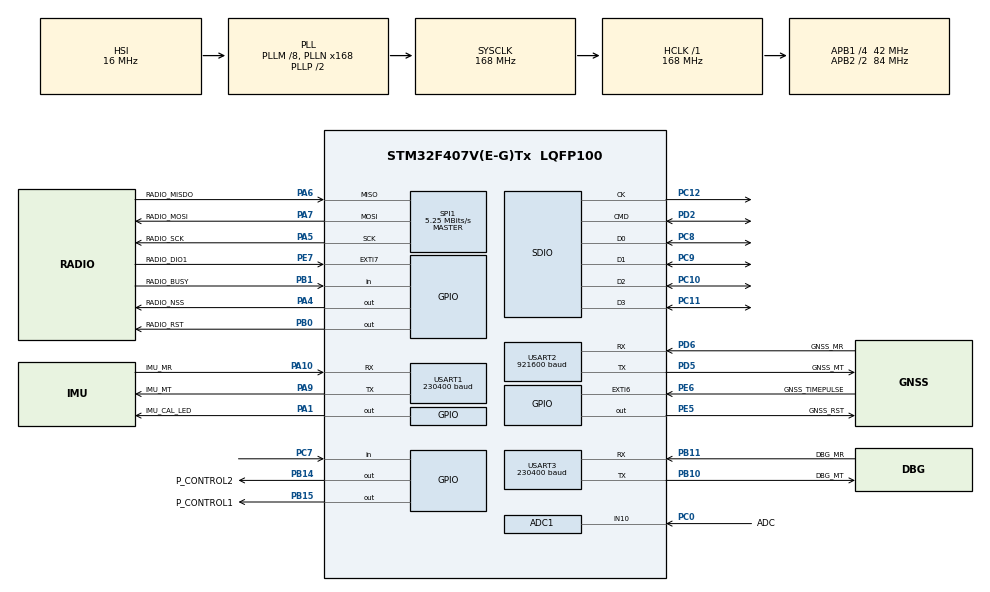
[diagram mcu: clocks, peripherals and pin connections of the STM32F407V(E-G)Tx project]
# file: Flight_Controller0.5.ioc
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ADC1.Channel-2\#ChannelRegularConversion=ADC_CHANNEL_10
ADC1.NbrOfConversionFlag=1
ADC1.Rank-2\#ChannelRegularConversion=1
ADC1.SamplingTime-2\#ChannelRegularConversion=ADC_SAMPLETIME_56CYCLES
ADC1.master=1
Dma.Request0=USART1_RX
Dma.Request1=USART1_TX
Dma.Request2=USART2_RX
Dma.Request3=USART2_TX
Dma.Request4=USART3_RX
Dma.Request5=USART3_TX
Dma.Request6=SDIO_RX
Dma.Request7=SDIO_TX
Dma.SDIO_RX.6.Direction=DMA_PERIPH_TO_MEMORY
Dma.SDIO_RX.6.FIFOMode=DMA_FIFOMODE_ENABLE
Dma.SDIO_RX.6.FIFOThreshold=DMA_FIFO_THRESHOLD_FULL
Dma.SDIO_RX.6.Instance=DMA2_Stream3
Dma.SDIO_RX.6.MemBurst=DMA_MBURST_INC4
Dma.SDIO_RX.6.MemDataAlignment=DMA_MDATAALIGN_WORD
Dma.SDIO_RX.6.MemInc=DMA_MINC_ENABLE
Dma.SDIO_RX.6.Mode=DMA_PFCTRL
Dma.SDIO_RX.6.PeriphBurst=DMA_PBURST_INC4
Dma.SDIO_RX.6.PeriphDataAlignment=DMA_PDATAALIGN_WORD
Dma.SDIO_RX.6.PeriphInc=DMA_PINC_DISABLE
Dma.SDIO_RX.6.Priority=DMA_PRIORITY_HIGH
Dma.SDIO_TX.7.Direction=DMA_MEMORY_TO_PERIPH
Dma.SDIO_TX.7.FIFOMode=DMA_FIFOMODE_ENABLE
Dma.SDIO_TX.7.FIFOThreshold=DMA_FIFO_THRESHOLD_FULL
Dma.SDIO_TX.7.Instance=DMA2_Stream6
Dma.SDIO_TX.7.MemBurst=DMA_MBURST_INC4
Dma.SDIO_TX.7.MemDataAlignment=DMA_MDATAALIGN_WORD
Dma.SDIO_TX.7.MemInc=DMA_MINC_ENABLE
Dma.SDIO_TX.7.Mode=DMA_PFCTRL
Dma.SDIO_TX.7.PeriphBurst=DMA_PBURST_INC4
Dma.SDIO_TX.7.PeriphDataAlignment=DMA_PDATAALIGN_WORD
Dma.SDIO_TX.7.PeriphInc=DMA_PINC_DISABLE
Dma.SDIO_TX.7.Priority=DMA_PRIORITY_HIGH
Dma.USART1_RX.0.Direction=DMA_PERIPH_TO_MEMORY
Dma.USART1_RX.0.FIFOMode=DMA_FIFOMODE_DISABLE
Dma.USART1_RX.0.Instance=DMA2_Stream2
Dma.USART1_RX.0.MemDataAlignment=DMA_MDATAALIGN_BYTE
Dma.USART1_RX.0.MemInc=DMA_MINC_ENABLE
Dma.USART1_RX.0.Mode=DMA_CIRCULAR
Dma.USART1_RX.0.PeriphDataAlignment=DMA_PDATAALIGN_BYTE
Dma.USART1_RX.0.PeriphInc=DMA_PINC_DISABLE
Dma.USART1_RX.0.Priority=DMA_PRIORITY_HIGH
Dma.USART1_TX.1.Direction=DMA_MEMORY_TO_PERIPH
Dma.USART1_TX.1.FIFOMode=DMA_FIFOMODE_DISABLE
Dma.USART1_TX.1.Instance=DMA2_Stream7
Dma.USART1_TX.1.MemDataAlignment=DMA_MDATAALIGN_BYTE
Dma.USART1_TX.1.MemInc=DMA_MINC_ENABLE
Dma.USART1_TX.1.Mode=DMA_NORMAL
Dma.USART1_TX.1.PeriphDataAlignment=DMA_PDATAALIGN_BYTE
Dma.USART1_TX.1.PeriphInc=DMA_PINC_DISABLE
Dma.USART1_TX.1.Priority=DMA_PRIORITY_HIGH
Dma.USART2_RX.2.Direction=DMA_PERIPH_TO_MEMORY
Dma.USART2_RX.2.FIFOMode=DMA_FIFOMODE_DISABLE
Dma.USART2_RX.2.Instance=DMA1_Stream5
Dma.USART2_RX.2.MemDataAlignment=DMA_MDATAALIGN_BYTE
Dma.USART2_RX.2.MemInc=DMA_MINC_ENABLE
Dma.USART2_RX.2.Mode=DMA_CIRCULAR
Dma.USART2_RX.2.PeriphDataAlignment=DMA_PDATAALIGN_BYTE
Dma.USART2_RX.2.PeriphInc=DMA_PINC_DISABLE
Dma.USART2_RX.2.Priority=DMA_PRIORITY_HIGH
Dma.USART2_TX.3.Direction=DMA_MEMORY_TO_PERIPH
Dma.USART2_TX.3.FIFOMode=DMA_FIFOMODE_DISABLE
Dma.USART2_TX.3.Instance=DMA1_Stream6
Dma.USART2_TX.3.MemDataAlignment=DMA_MDATAALIGN_BYTE
Dma.USART2_TX.3.MemInc=DMA_MINC_ENABLE
Dma.USART2_TX.3.Mode=DMA_NORMAL
Dma.USART2_TX.3.PeriphDataAlignment=DMA_PDATAALIGN_BYTE
Dma.USART2_TX.3.PeriphInc=DMA_PINC_DISABLE
Dma.USART2_TX.3.Priority=DMA_PRIORITY_HIGH
Dma.USART3_RX.4.Direction=DMA_PERIPH_TO_MEMORY
Dma.USART3_RX.4.FIFOMode=DMA_FIFOMODE_DISABLE
Dma.USART3_RX.4.Instance=DMA1_Stream1
Dma.USART3_RX.4.MemDataAlignment=DMA_MDATAALIGN_BYTE
Dma.USART3_RX.4.MemInc=DMA_MINC_ENABLE
Dma.USART3_RX.4.Mode=DMA_CIRCULAR
Dma.USART3_RX.4.PeriphDataAlignment=DMA_PDATAALIGN_BYTE
Dma.USART3_RX.4.PeriphInc=DMA_PINC_DISABLE
Dma.USART3_RX.4.Priority=DMA_PRIORITY_LOW
Dma.USART3_TX.5.Direction=DMA_MEMORY_TO_PERIPH
Dma.USART3_TX.5.FIFOMode=DMA_FIFOMODE_DISABLE
Dma.USART3_TX.5.Instance=DMA1_Stream3
Dma.USART3_TX.5.MemDataAlignment=DMA_MDATAALIGN_BYTE
Dma.USART3_TX.5.MemInc=DMA_MINC_ENABLE
Dma.USART3_TX.5.Mode=DMA_NORMAL
Dma.USART3_TX.5.PeriphDataAlignment=DMA_PDATAALIGN_BYTE
Dma.USART3_TX.5.PeriphInc=DMA_PINC_DISABLE
Dma.USART3_TX.5.Priority=DMA_PRIORITY_LOW
FATFS.BSP.number=1
FATFS0.BSP.STBoard=false
FATFS0.BSP.api=Unknown
FATFS0.BSP.instance=PC7
FATFS0.BSP.ip=GPIO
FATFS0.BSP.mode=Input
FATFS0.BSP.name=Detect_SDIO
FATFS0.BSP.solution=PC7
Mcu.Family=STM32F4
Mcu.Name=STM32F407V(E-G)Tx
Mcu.Package=LQFP100
NVIC.DMA1_Stream1_IRQn=true\:5\:0\:false\:false\:true\:true\:false\:true\:true
NVIC.DMA1_Stream3_IRQn=true\:5\:0\:false\:false\:true\:true\:false\:true\:true
NVIC.DMA1_Stream5_IRQn=true\:5\:0\:false\:false\:true\:true\:false\:true\:true
NVIC.DMA1_Stream6_IRQn=true\:5\:0\:false\:false\:true\:true\:false\:true\:true
NVIC.DMA2_Stream2_IRQn=true\:5\:0\:false\:false\:true\:true\:false\:true\:true
NVIC.DMA2_Stream3_IRQn=true\:5\:0\:false\:false\:true\:true\:false\:true\:true
NVIC.DMA2_Stream6_IRQn=true\:5\:0\:false\:false\:true\:true\:false\:true\:true
NVIC.DMA2_Stream7_IRQn=true\:5\:0\:false\:false\:true\:true\:false\:true\:true
NVIC.EXTI9_5_IRQn=true\:5\:0\:false\:false\:true\:true\:true\:true\:true
NVIC.PriorityGroup=NVIC_PRIORITYGROUP_4
NVIC.SDIO_IRQn=true\:6\:0\:true\:false\:true\:true\:true\:true\:true
NVIC.TIM1_UP_TIM10_IRQn=true\:15\:0\:false\:false\:true\:false\:false\:true\:true
NVIC.TimeBase=TIM1_UP_TIM10_IRQn
NVIC.TimeBaseIP=TIM1
NVIC.USART1_IRQn=true\:5\:0\:false\:false\:true\:true\:false\:true\:true
NVIC.USART2_IRQn=true\:5\:0\:false\:false\:true\:true\:false\:true\:true
NVIC.USART3_IRQn=true\:5\:0\:false\:false\:true\:true\:false\:true\:true
PA1.GPIO_Label=IMU_CAL_LED
PA1.PinState=GPIO_PIN_SET
PA1.Signal=GPIO_Output
PA10.GPIO_Label=IMU_MR
PA10.Mode=Asynchronous
PA10.Signal=USART1_RX
PA13.Mode=Serial_Wire
PA13.Signal=SYS_JTMS-SWDIO
PA14.Mode=Serial_Wire
PA14.Signal=SYS_JTCK-SWCLK
PA4.GPIO_Label=RADIO_NSS
PA4.PinState=GPIO_PIN_SET
PA4.Signal=GPIO_Output
PA5.GPIO_Label=RADIO_SCK
PA5.Mode=Full_Duplex_Master
PA5.Signal=SPI1_SCK
PA6.GPIO_Label=RADIO_MISDO
PA6.Mode=Full_Duplex_Master
PA6.Signal=SPI1_MISO
PA7.GPIO_Label=RADIO_MOSI
PA7.Mode=Full_Duplex_Master
PA7.Signal=SPI1_MOSI
PA9.GPIO_Label=IMU_MT
PA9.Mode=Asynchronous
PA9.Signal=USART1_TX
PB0.GPIO_Label=RADIO_RST
PB0.PinState=GPIO_PIN_SET
PB0.Signal=GPIO_Output
PB1.GPIO_Label=RADIO_BUSY
PB1.Signal=GPIO_Input
PB10.GPIO_Label=DBG_MT
PB10.Mode=Asynchronous
PB10.Signal=USART3_TX
PB11.GPIO_Label=DBG_MR
PB11.Mode=Asynchronous
PB11.Signal=USART3_RX
PB14.GPIO_Label=P_CONTROL2
PB14.Signal=GPIO_Output
PB15.GPIO_Label=P_CONTROL1
PB15.Signal=GPIO_Output
PC0.GPIO_Label=ADC
PC0.Signal=ADCx_IN10
PC10.GPIO_PuPd=GPIO_PULLUP
PC10.Mode=SD_4_bits_Wide_bus
PC10.Signal=SDIO_D2
PC11.GPIO_PuPd=GPIO_PULLUP
PC11.Mode=SD_4_bits_Wide_bus
PC11.Signal=SDIO_D3
PC12.Mode=SD_4_bits_Wide_bus
PC12.Signal=SDIO_CK
PC7.GPIO_PuPd=GPIO_PULLDOWN
PC7.Signal=GPIO_Input
PC8.GPIO_PuPd=GPIO_PULLUP
PC8.Mode=SD_4_bits_Wide_bus
PC8.Signal=SDIO_D0
PC9.GPIO_PuPd=GPIO_PULLUP
PC9.Mode=SD_4_bits_Wide_bus
PC9.Signal=SDIO_D1
PD2.GPIO_PuPd=GPIO_PULLUP
PD2.Mode=SD_4_bits_Wide_bus
PD2.Signal=SDIO_CMD
PD5.GPIO_Label=GNSS_MT
PD5.Mode=Asynchronous
PD5.Signal=USART2_TX
PD6.GPIO_Label=GNSS_MR
PD6.Mode=Asynchronous
PD6.Signal=USART2_RX
PE5.GPIO_Label=GNSS_RST
PE5.PinState=GPIO_PIN_SET
PE5.Signal=GPIO_Output
PE6.GPIO_Label=GNSS_TIMEPULSE
PE6.Signal=GPXTI6
PE7.GPIO_Label=RADIO_DIO1
PE7.Signal=GPXTI7
PH0-OSC_IN.Mode=HSE-External-Oscillator
PH0-OSC_IN.Signal=RCC_OSC_IN
PH1-OSC_OUT.Mode=HSE-External-Oscillator
PH1-OSC_OUT.Signal=RCC_OSC_OUT
ProjectManager.HeapSize=0x0
ProjectManager.StackSize=0x400
ProjectManager.TargetToolchain=Makefile
RCC.48MHZClocksFreq_Value=48000000
RCC.AHBFreq_Value=168000000
RCC.APB1CLKDivider=RCC_HCLK_DIV4
RCC.APB1Freq_Value=42000000
RCC.APB1TimFreq_Value=84000000
RCC.APB2CLKDivider=RCC_HCLK_DIV2
RCC.APB2Freq_Value=84000000
RCC.APB2TimFreq_Value=168000000
RCC.CortexFreq_Value=168000000
RCC.HCLKFreq_Value=168000000
RCC.HSE_VALUE=25000000
RCC.HSI_VALUE=16000000
RCC.LSE_VALUE=32768
RCC.PLLM=8
RCC.PLLN=168
RCC.PLLQ=7
RCC.SYSCLKFreq_VALUE=168000000
RCC.SYSCLKSource=RCC_SYSCLKSOURCE_PLLCLK
RCC.VCOOutputFreq_Value=336000000
SH.ADCx_IN10.0=ADC1_IN10,IN10
SPI1.BaudRatePrescaler=SPI_BAUDRATEPRESCALER_16
SPI1.CalculateBaudRate=5.25 MBits/s
SPI1.Direction=SPI_DIRECTION_2LINES
SPI1.Mode=SPI_MODE_MASTER
SPI1.VirtualType=VM_MASTER
USART1.BaudRate=230400
USART1.VirtualMode=VM_ASYNC
USART2.BaudRate=921600
USART2.VirtualMode=VM_ASYNC
USART3.BaudRate=230400
USART3.VirtualMode=VM_ASYNC
VP_FATFS_VS_SDIO.Mode=SDIO
VP_SYS_VS_tim1.Mode=TIM1
board=custom

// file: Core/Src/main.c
/* USER CODE BEGIN Header */
/**
  ******************************************************************************
  * @file           : main.c
  * @brief          : Main program body
  ******************************************************************************
  * @attention
  *
  * Copyright (c) 2026 STMicroelectronics.
  * All rights reserved.
  *
  * This software is licensed under terms that can be found in the LICENSE file
  * in the root directory of this software component.
  * If no LICENSE file comes with this software, it is provided AS-IS.
  *
  ******************************************************************************
  */
/* USER CODE END Header */
#include "main.h"
#include "adc.h"
#include "dma.h"
#include "fatfs.h"
#include "sdio.h"
#include "spi.h"
#include "usart.h"
#include "gpio.h"

/* USER CODE BEGIN Includes */
#include "FreeRTOS.h"
#include "app_tasks.h"
#include "system_version.h"
#include "debug_log.h"
#include "system_startup.h"
#include "task.h"
/* USER CODE END Includes */

void SystemClock_Config(void);

int main(void)
{

  /* MCU Configuration--------------------------------------------------------*/

  /* Reset of all peripherals, Initializes the Flash interface and the Systick. */
  HAL_Init();

  /* Configure the system clock */
  SystemClock_Config();

  /* Initialize all configured peripherals */
  MX_GPIO_Init();
  MX_DMA_Init();
  MX_USART1_UART_Init();
  MX_USART2_UART_Init();
  MX_USART3_UART_Init();
  MX_SPI1_Init();
  MX_ADC1_Init();
  MX_SDIO_SD_Init();
  MX_FATFS_Init();
  /* USER CODE BEGIN 2 */
  {
    SystemStartupResult startup_result = SystemStartup_Run();

    if (SystemStartup_ResultIsFatal(startup_result) != 0U)
    {
      Error_Handler();
    }
  }
  /* USER CODE END 2 */

  /* Initialize the statically allocated SilverStar tasks and start FreeRTOS. */
  if (AppTasks_Init() != AppTasksInitResult_Ok)
  {
    Error_Handler();
  }
  vTaskStartScheduler();

  /* We should never get here as control is now taken by the scheduler */
  Error_Handler();

  /* Infinite loop */
  while (1)
  {

  }
}

void SystemClock_Config(void)
{
  RCC_OscInitTypeDef RCC_OscInitStruct = {0};
  RCC_ClkInitTypeDef RCC_ClkInitStruct = {0};

  /** Configure the main internal regulator output voltage
  */
  __HAL_RCC_PWR_CLK_ENABLE();
  __HAL_PWR_VOLTAGESCALING_CONFIG(PWR_REGULATOR_VOLTAGE_SCALE1);

  /** Initializes the RCC Oscillators according to the specified parameters
  * in the RCC_OscInitTypeDef structure.
  */
  RCC_OscInitStruct.OscillatorType = RCC_OSCILLATORTYPE_HSI;
  RCC_OscInitStruct.HSIState = RCC_HSI_ON;
  RCC_OscInitStruct.HSICalibrationValue = RCC_HSICALIBRATION_DEFAULT;
  RCC_OscInitStruct.PLL.PLLState = RCC_PLL_ON;
  RCC_OscInitStruct.PLL.PLLSource = RCC_PLLSOURCE_HSI;
  RCC_OscInitStruct.PLL.PLLM = 8;
  RCC_OscInitStruct.PLL.PLLN = 168;
  RCC_OscInitStruct.PLL.PLLP = RCC_PLLP_DIV2;
  RCC_OscInitStruct.PLL.PLLQ = 7;
  if (HAL_RCC_OscConfig(&RCC_OscInitStruct) != HAL_OK)
  {
    Error_Handler();
  }

  /** Initializes the CPU, AHB and APB buses clocks
  */
  RCC_ClkInitStruct.ClockType = RCC_CLOCKTYPE_HCLK|RCC_CLOCKTYPE_SYSCLK
                              |RCC_CLOCKTYPE_PCLK1|RCC_CLOCKTYPE_PCLK2;
  RCC_ClkInitStruct.SYSCLKSource = RCC_SYSCLKSOURCE_PLLCLK;
  RCC_ClkInitStruct.AHBCLKDivider = RCC_SYSCLK_DIV1;
  RCC_ClkInitStruct.APB1CLKDivider = RCC_HCLK_DIV4;
  RCC_ClkInitStruct.APB2CLKDivider = RCC_HCLK_DIV2;

  if (HAL_RCC_ClockConfig(&RCC_ClkInitStruct, FLASH_LATENCY_5) != HAL_OK)
  {
    Error_Handler();
  }
}

void HAL_TIM_PeriodElapsedCallback(TIM_HandleTypeDef *htim)
{
  if (htim->Instance == TIM1)
  {
    HAL_IncTick();
  }
}

void Error_Handler(void)
{
  __disable_irq();
  while (1)
  {
  }
}
